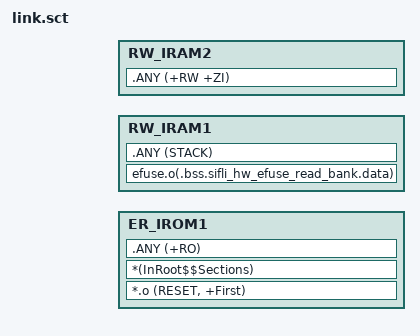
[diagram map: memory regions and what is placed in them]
#! armclang -E --target=arm-arm-none-eabi -mcpu=cortex-m33 -xc -I ../../../../../drivers/cmsis/sf32lb57x
#include "mem_map.h"
#include "../rtconfig.h"

; *************************************************************
; *** Scatter-Loading Description File generated by uVision ***
; *************************************************************

LR_IROM1 BOOTLOADER_CODE_START_ADDR BOOTLOADER_CODE_SIZE {    ; load region size_region, 
  ER_IROM1 BOOTLOADER_CODE_START_ADDR BOOTLOADER_CODE_SIZE {  ; load address = execution address
   *.o (RESET, +First)
   *(InRoot$$Sections)
   .ANY (+RO)
  }

  ; 0x20000000 to 0x0x20001020 will be overwritten when wake up from Standby and before Jump to RAM code.
  ; so do not put retained data in this region if using standby mode
  RW_IRAM1 BOOTLOADER_RAM_DATA_START_ADDR  {  
     efuse.o(.bss.sifli_hw_efuse_read_bank.data)
     .ANY (STACK)
  }
  RW_IRAM2 +0 BOOTLOADER_RAM_DATA_SIZE  {  ; RW data
     .ANY (+RW +ZI)
  }
}
